# GD32F1x0 register map
File version: 1.0
CPU: CM3 r2p1, little endian, no MPU, no FPU, 4 interrupt priority bits
Registers are 32-bit, read-write, reset 0x0 unless marked. A register's access mark holds for its fields unless they carry their own. Offsets are from the block's base; [hi:lo] are bit positions; lines under a group give offsets from that group; {n}, {i} and the like mark numbered series.

## TSI — Touch sensing Interface
Base 0x40024000
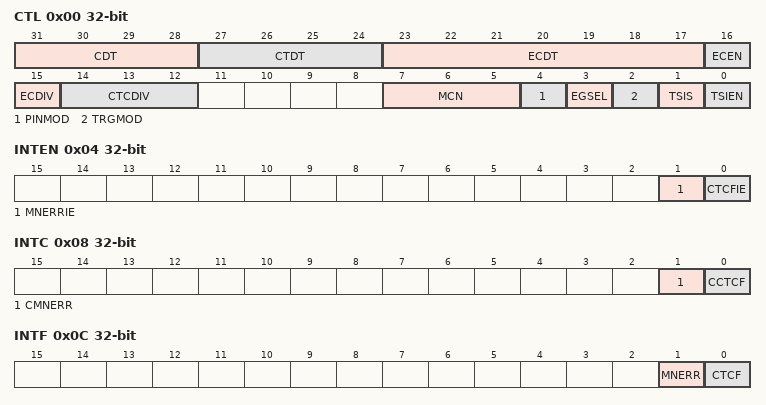
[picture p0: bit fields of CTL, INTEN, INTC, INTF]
0x00 CTL — control register
  [31:28] CDT — Charge State Duration Time
  [27:24] CTDT — Charge Transfer State Duration Time
  [23:17] ECDT — Extend Charge State Maximum Duration Time
  [16] ECEN — Extend Charge State Enable
  [15] ECDIV — ECCLK clock division factor
  [14:12] CTCDIV — CTCLK clock division factor
  [7:5] MCN — Max cycle number of a sequence
  [4] PINMOD — Pin mode
  [3] EGSEL — Edge selection
  [2] TRGMOD — Trigger mode selection
  [1] TSIS — TSI start
  [0] TSIEN — TSI enable
0x04 INTEN — interrupt enable register
  [1] MNERRIE — Max Cycle Number Error Interrupt Enable
  [0] CTCFIE — Charge-transfer complete flag Interrupt Enable
0x08 INTC wo — interrupt flag clear register
  [1] CMNERR — Clear max cycle number error
  [0] CCTCF — Clear charge-transfer complete flag
0x0C INTF ro — interrupt flag register
  [1] MNERR — Max count error flag
  [0] CTCF — Charge-Transfer complete flag
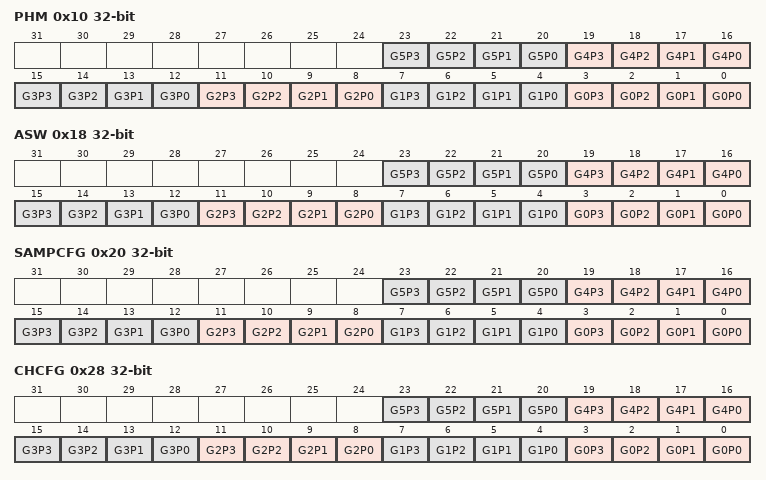
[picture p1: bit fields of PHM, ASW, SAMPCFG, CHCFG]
0x10 PHM — Pin hysteresis mode register
  [4n+3] G{n}P3 (n=0..5) — G{n}P3 Schmitt trigger hysteresis mode
  [4n+2] G{n}P2 (n=0..5) — G{n}P2 Schmitt trigger hysteresis mode
  [4n+1] G{n}P1 (n=0..5) — G{n}P1 Schmitt trigger hysteresis mode
  [4n] G{n}P0 (n=0..5) — G{n}P0 Schmitt trigger hysteresis mode
0x18 ASW — I/O analog switch register
  [4n+3] G{n}P3 (n=0..5) — G{n}P3 analog switch enable
  [4n+2] G{n}P2 (n=0..5) — G{n}P2 analog switch enable
  [4n+1] G{n}P1 (n=0..5) — G{n}P1 analog switch enable
  [4n] G{n}P0 (n=0..5) — G{n}P0 analog switch enable
0x20 SAMPCFG — I/O sample configuration register
  [4n+3] G{n}P3 (n=0..5) — G{n}P3 sampling mode
  [4n+2] G{n}P2 (n=0..5) — G{n}P2 sampling mode
  [4n+1] G{n}P1 (n=0..5) — G{n}P1 sampling mode
  [4n] G{n}P0 (n=0..5) — G{n}P0 sampling mode
0x28 CHCFG — I/O channel configuration register
  [4n+3] G{n}P3 (n=0..5) — G{n}P3 channel mode
  [4n+2] G{n}P2 (n=0..5) — G{n}P2 channel mode
  [4n+1] G{n}P1 (n=0..5) — G{n}P1 channel mode
  [4n] G{n}P0 (n=0..5) — G{n}P0 channel mode
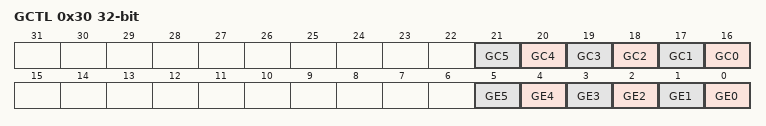
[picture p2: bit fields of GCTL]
0x30 GCTL access per field — I/O group control register
  [n+16] GC{n} ro (n=0..5) — Analog I/O group {n} status
  [n] GE{n} rw (n=0..5) — Analog I/O group {n} enable
{0x34+4i} G{i}CYCN (i=0..5) — I/O group x cycle number register
  [13:0] CYCN — Cycle number

## USART1 — Universal synchronous asynchronous receiver transmitter
Base 0x40004400
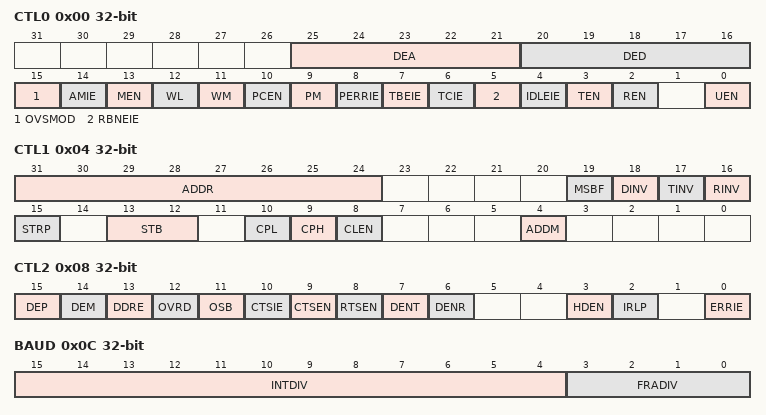
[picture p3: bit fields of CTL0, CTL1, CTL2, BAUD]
0x00 CTL0 — Control register 0
  [25:21] DEA — Driver Enable assertion time
  [20:16] DED — Driver Enable deassertion time
  [15] OVSMOD — Oversampling mode
  [14] AMIE — ADDR match interrupt enable
  [13] MEN — Mute mode enable
  [12] WL — Word length
  [11] WM — Wakeup method in mute mode
  [10] PCEN — Parity control enable
  [9] PM — Parity selection
  [8] PERRIE — Parity error interrupt enable
  [7] TBEIE — Transmitter register empty interrupt enable
  [6] TCIE — Transmission complete interrupt enable
  [5] RBNEIE — Read data buffer not empty interrupt and overrun error interrupt enable
  [4] IDLEIE — IDLE line detected interrupt enable
  [3] TEN — Transmitter enable
  [2] REN — Receiver enable
  [0] UEN — USART enable
0x04 CTL1 — Control register 1
  [31:24] ADDR — Address of the USART terminal
  [19] MSBF — Most significant bit first
  [18] DINV — Data bit level inversion
  [17] TINV — TX pin level inversion
  [16] RINV — RX pin level inversion
  [15] STRP — Swap TX/RX pins
  [13:12] STB — STOP bits length
  [10] CPL — Clock polarity
  [9] CPH — Clock phase
  [8] CLEN — CK length
  [4] ADDM — Address detection mode
0x08 CTL2 — Control register 2
  [15] DEP — Driver enable polarity mode
  [14] DEM — Driver enable mode
  [13] DDRE — Disable DMA on reception error
  [12] OVRD — Overrun Disable
  [11] OSB — One sample bit method
  [10] CTSIE — CTS interrupt enable
  [9] CTSEN — CTS enable
  [8] RTSEN — RTS enable
  [7] DENT — DMA enable transmitter
  [6] DENR — DMA enable for reception
  [3] HDEN — Half-duplex selection
  [2] IRLP — IrDA low-power
  [0] ERRIE — Error interrupt enable
0x0C BAUD — Baud rate generator register
  [15:4] INTDIV — Integer part of baud-rate divider
  [3:0] FRADIV — Fraction part of baud-rate divider
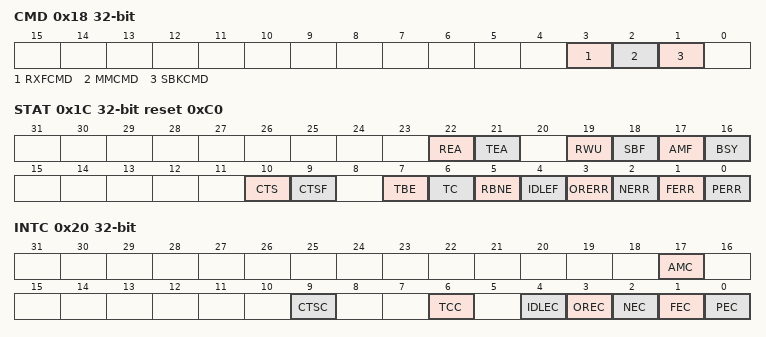
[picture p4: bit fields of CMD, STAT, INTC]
0x18 CMD wo — Request register
  [3] RXFCMD — Receive data flush command
  [2] MMCMD — Mute mode command
  [1] SBKCMD — Send break command
0x1C STAT ro reset 0xC0 — Interrupt & status register
  [22] REA — Receive enable acknowledge flag
  [21] TEA — Transmit enable acknowledge flag
  [19] RWU — Receiver wakeup from Mute mode
  [18] SBF — Send break flag
  [17] AMF — ADDR match flag
  [16] BSY — Busy flag
  [10] CTS — CTS level
  [9] CTSF — CTS change flag
  [7] TBE — Transmit data register empty
  [6] TC — Transmission complete
  [5] RBNE — Read data buffer not empty
  [4] IDLEF — IDLE line detected flag
  [3] ORERR — Overrun error
  [2] NERR — Noise error flag
  [1] FERR — Frame error flag
  [0] PERR — Parity error flag
0x20 INTC wo — Interrupt flag clear register
  [17] AMC — ADDR match clear
  [9] CTSC — CTS change clear
  [6] TCC — Transmission complete clear flag
  [4] IDLEC — Idle line detected clear
  [3] OREC — Overrun error clear flag
  [2] NEC — Noise detected clear
  [1] FEC — Framing error clear flag
  [0] PEC — Parity error clear flag
0x24 RDATA ro — Receive data register
  [8:0] RDATA — Receive data value
0x28 TDATA — Transmit data register
  [8:0] TDATA — Transmit data value

## USBD — Universal serial bus full-speed device interface
Base 0x40005C00
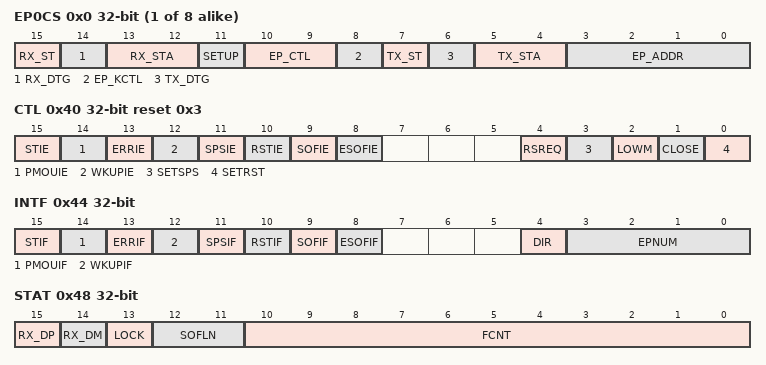
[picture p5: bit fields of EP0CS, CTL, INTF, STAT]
{0x0+4i} EP{i}CS access per field (i=0..7) — endpoint {i} register
  [15] RX_ST rw — Reception Successful Transferred
  [14] RX_DTG rw — Reception Data PID Toggle
  [13:12] RX_STA rw — Reception status bits
  [11] SETUP ro — Setup transaction completed
  [10:9] EP_CTL rw — Endpoint type control
  [8] EP_KCTL rw — Endpoint kind control
  [7] TX_ST rw — Transmission Successful Transfer
  [6] TX_DTG rw — Transmission Data PID Toggle
  [5:4] TX_STA rw — Status bits, for transmission transfers
  [3:0] EP_ADDR rw — Endpoint address
0x40 CTL reset 0x3 — control register
  [15] STIE — Successful transfer interrupt enable
  [14] PMOUIE — Packet memory overrun / underrun interrupt enable
  [13] ERRIE — Error interrupt mask
  [12] WKUPIE — Wakeup interrupt mask
  [11] SPSIE — Suspend state interrupt enable
  [10] RSTIE — USB reset interrupt enable
  [9] SOFIE — Start of frame interrupt enable
  [8] ESOFIE — Expected start of frame interrupt enable
  [4] RSREQ — Send resume request
  [3] SETSPS — Set suspend state
  [2] LOWM — Low-power mode
  [1] CLOSE — USB close
  [0] SETRST — USB Reset
0x44 INTF access per field — interrupt flag register
  [15] STIF ro — Successful transfer interrupt flag
  [14] PMOUIF rw — Packet memory overrun / underrun interrupt flag
  [13] ERRIF rw — Error interrupt flag
  [12] WKUPIF rw — Wakeup interrupt flag
  [11] SPSIF rw — Suspend state interrupt flag
  [10] RSTIF rw — USB reset interrupt flag
  [9] SOFIF rw — Start of frame interrupt flag
  [8] ESOFIF rw — Expected start of frame interrupt flag
  [4] DIR ro — Direction of transaction
  [3:0] EPNUM ro — Endpoint Number
0x48 STAT ro — Status register
  [15] RX_DP — Receive data + line status
  [14] RX_DM — Receive data - line status
  [13] LOCK — Locked the USB
  [12:11] SOFLN — SOF lost number
  [10:0] FCNT — Frame number counter
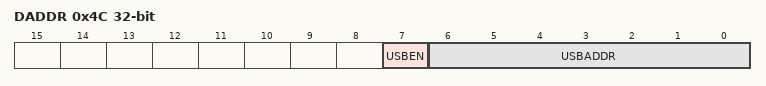
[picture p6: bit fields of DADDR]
0x4C DADDR — device address register
  [7] USBEN — USB device enable
  [6:0] USBADDR — USB device address
0x50 BADDR — Buffer address register
  [15:3] BAR — Buffer address

## WWDGT — Window watchdog timer
Base 0x40002C00
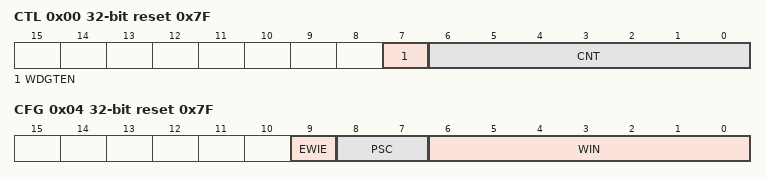
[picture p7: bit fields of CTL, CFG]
0x00 CTL reset 0x7F — Control register
  [7] WDGTEN — Start the Window watchdog timer
  [6:0] CNT — watchdog timer counter
0x04 CFG reset 0x7F — Configuration register
  [9] EWIE — Early wakeup interrupt enable
  [8:7] PSC — Prescaler
  [6:0] WIN — The Window value
0x08 STAT — Status register
  [0] EWIF — EEarly wakeup interrupt flag
